AUTOSAR XML (schema 4-2-1)
package /ComponentTypes
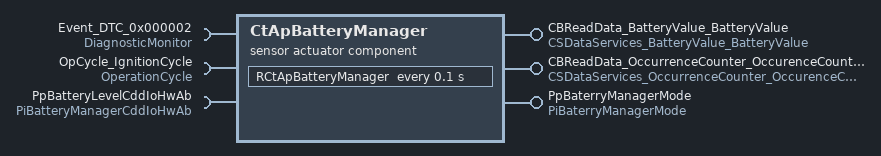
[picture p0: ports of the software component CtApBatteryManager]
  sensor actuator sw component type CtApBatteryManager
    provide port CBReadData_BatteryValue_BatteryValue: server-com-spec{operation=ReadData, queue-length=1}, provided-interface=CSDataServices_BatteryValue_BatteryValue
    provide port CBReadData_OccurrenceCounter_OccurenceCounter: server-com-spec{operation=ReadData, queue-length=1}, provided-interface=CSDataServices_OccurrenceCounter_OccurenceCounter
    provide port PpBaterryManagerMode: mode-switch-sender-com-spec{enhanced-mode-api=false, mode-group=Mode, queue-length=1}, provided-interface=PiBaterryManagerMode
    require port Event_DTC_0x000002: required-interface=DiagnosticMonitor
    require port OpCycle_IgnitionCycle: required-interface=OperationCycle
    require port PpBatteryLevelCddIoHwAb: required-interface=PiBatteryManagerCddIoHwAb
    behavior CtApBatteryManager_InternalBehavior
      operation invoked event OIT_CBReadData_BatteryValue_BatteryValue_ReadData_CBReadData_BatteryValue_BatteryValue_ReadData: start-on-event=CBReadData_BatteryValue_BatteryValue_ReadData, operation=CBReadData_BatteryValue_BatteryValue.ReadData
      operation invoked event OIT_CBReadData_OccurrenceCounter_OccurenceCounter_ReadData_CBReadData_OccurrenceCounter_OccurenceCounter_ReadData: start-on-event=CBReadData_OccurrenceCounter_OccurenceCounter_ReadData, operation=CBReadData_OccurrenceCounter_OccurenceCounter.ReadData
      init event CtApBatteryManager_InitEvent: start-on-event=CtApBatteryManager_Init
      timing event TMT_RCtApBatteryManager: start-on-event=RCtApBatteryManager, period=0.1
      4 x runnable:
        CBReadData_BatteryValue_BatteryValue_ReadData
        CBReadData_OccurrenceCounter_OccurenceCounter_ReadData
        CtApBatteryManager_Init
          sync call SC_OpCycle_IgnitionCycle_SetOperationCycleState: operation=OpCycle_IgnitionCycle.SetOperationCycleState, timeout=0
        RCtApBatteryManager
          mode switch point SWITCH_PpBaterryManagerMode_Mode: mode-group=PpBaterryManagerMode.Mode
          sync call SC_Event_DTC_0x000002_SetEventStatus: operation=Event_DTC_0x000002.SetEventStatus, timeout=0
          sync call SC_PpBatteryLevelCddIoHwAb_ReadChannel: operation=PpBatteryLevelCddIoHwAb.ReadChannel, timeout=0
  swc implementation CtApBatteryManager_Implementation: behavior=CtApBatteryManager_InternalBehavior
    code-descriptors:
      code Default: artifact-descriptors=autosar-engineering-object={short-label=Default, category=SWSRC}
